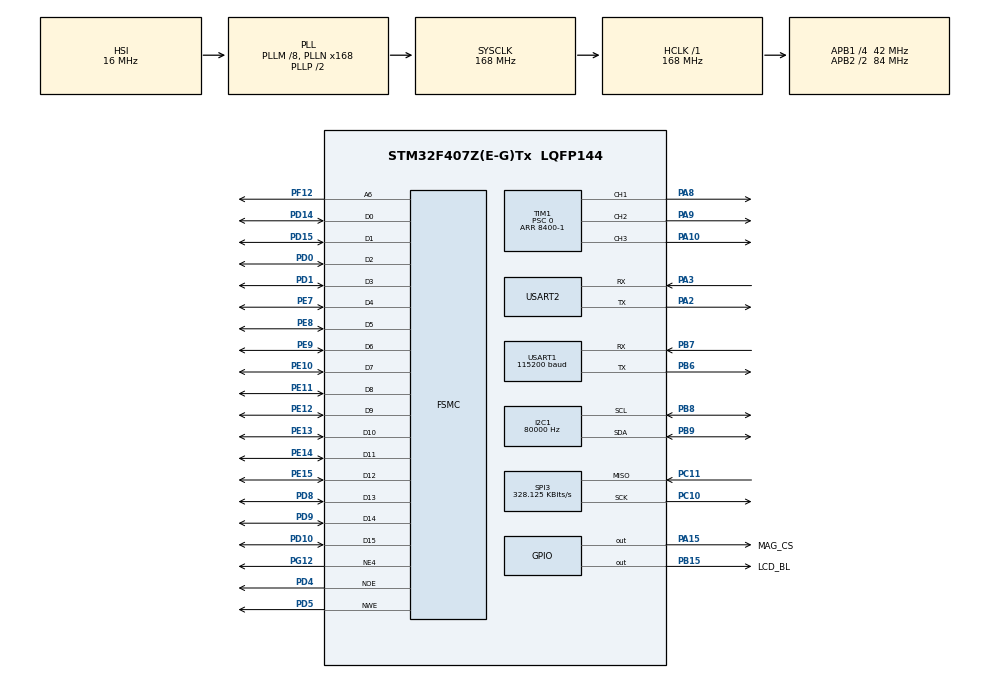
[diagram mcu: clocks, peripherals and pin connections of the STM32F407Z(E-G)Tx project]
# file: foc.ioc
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Dma.Request0=USART1_TX
Dma.Request1=USART2_RX
Dma.Request2=USART2_TX
Dma.USART1_TX.0.Direction=DMA_MEMORY_TO_PERIPH
Dma.USART1_TX.0.FIFOMode=DMA_FIFOMODE_DISABLE
Dma.USART1_TX.0.Instance=DMA2_Stream7
Dma.USART1_TX.0.MemDataAlignment=DMA_MDATAALIGN_BYTE
Dma.USART1_TX.0.MemInc=DMA_MINC_ENABLE
Dma.USART1_TX.0.Mode=DMA_NORMAL
Dma.USART1_TX.0.PeriphDataAlignment=DMA_PDATAALIGN_BYTE
Dma.USART1_TX.0.PeriphInc=DMA_PINC_DISABLE
Dma.USART1_TX.0.Priority=DMA_PRIORITY_LOW
Dma.USART2_RX.1.Direction=DMA_PERIPH_TO_MEMORY
Dma.USART2_RX.1.FIFOMode=DMA_FIFOMODE_DISABLE
Dma.USART2_RX.1.Instance=DMA1_Stream5
Dma.USART2_RX.1.MemDataAlignment=DMA_MDATAALIGN_BYTE
Dma.USART2_RX.1.MemInc=DMA_MINC_ENABLE
Dma.USART2_RX.1.Mode=DMA_NORMAL
Dma.USART2_RX.1.PeriphDataAlignment=DMA_PDATAALIGN_BYTE
Dma.USART2_RX.1.PeriphInc=DMA_PINC_DISABLE
Dma.USART2_RX.1.Priority=DMA_PRIORITY_LOW
Dma.USART2_TX.2.Direction=DMA_MEMORY_TO_PERIPH
Dma.USART2_TX.2.FIFOMode=DMA_FIFOMODE_DISABLE
Dma.USART2_TX.2.Instance=DMA1_Stream6
Dma.USART2_TX.2.MemDataAlignment=DMA_MDATAALIGN_BYTE
Dma.USART2_TX.2.MemInc=DMA_MINC_ENABLE
Dma.USART2_TX.2.Mode=DMA_NORMAL
Dma.USART2_TX.2.PeriphDataAlignment=DMA_PDATAALIGN_BYTE
Dma.USART2_TX.2.PeriphInc=DMA_PINC_DISABLE
Dma.USART2_TX.2.Priority=DMA_PRIORITY_LOW
FREERTOS.Tasks01=dbug_info,0,1000,dbug_info_fun,As weak,NULL,Dynamic,NULL,NULL;entey_task,3,512,entey_task_fun,As weak,NULL,Dynamic,NULL,NULL
FREERTOS.configENABLE_FPU=1
FREERTOS.configGENERATE_RUN_TIME_STATS=1
FREERTOS.configTOTAL_HEAP_SIZE=30000
FREERTOS.configUSE_RECURSIVE_MUTEXES=1
FREERTOS.configUSE_STATS_FORMATTING_FUNCTIONS=1
FREERTOS.configUSE_TRACE_FACILITY=1
FSMC.ExtendedMode1=FSMC_EXTENDED_MODE_ENABLE
I2C1.ClockSpeed=80000
I2C1.I2C_Mode=I2C_Standard
Mcu.Family=STM32F4
Mcu.Name=STM32F407Z(E-G)Tx
Mcu.Package=LQFP144
NVIC.DMA1_Stream5_IRQn=true\:5\:0\:false\:false\:true\:true\:false\:true\:true
NVIC.DMA1_Stream6_IRQn=true\:5\:0\:false\:false\:true\:true\:false\:true\:true
NVIC.DMA2_Stream7_IRQn=true\:5\:0\:false\:false\:true\:true\:false\:true\:true
NVIC.PriorityGroup=NVIC_PRIORITYGROUP_4
NVIC.TIM1_UP_TIM10_IRQn=true\:5\:0\:false\:false\:true\:true\:true\:true\:true
NVIC.TIM7_IRQn=true\:4\:0\:true\:false\:true\:false\:true\:true\:true
NVIC.TIM8_TRG_COM_TIM14_IRQn=true\:4\:0\:true\:false\:true\:false\:false\:true\:true
NVIC.TimeBase=TIM8_TRG_COM_TIM14_IRQn
NVIC.TimeBaseIP=TIM14
NVIC.USART1_IRQn=true\:5\:0\:false\:false\:true\:true\:true\:true\:true
NVIC.USART2_IRQn=true\:5\:0\:false\:false\:true\:true\:true\:true\:true
PA10.Signal=S_TIM1_CH3
PA13.Mode=Serial_Wire
PA13.Signal=SYS_JTMS-SWDIO
PA14.Mode=Serial_Wire
PA14.Signal=SYS_JTCK-SWCLK
PA15.GPIO_Label=MAG_CS
PA15.GPIO_PuPd=GPIO_PULLUP
PA15.GPIO_Speed=GPIO_SPEED_FREQ_VERY_HIGH
PA15.PinState=GPIO_PIN_SET
PA15.Signal=GPIO_Output
PA2.Mode=Asynchronous
PA2.Signal=USART2_TX
PA3.Mode=Asynchronous
PA3.Signal=USART2_RX
PA8.Signal=S_TIM1_CH1
PA9.Signal=S_TIM1_CH2
PB15.GPIO_Label=LCD_BL
PB15.GPIO_PuPd=GPIO_PULLUP
PB15.GPIO_Speed=GPIO_SPEED_FREQ_VERY_HIGH
PB15.PinState=GPIO_PIN_SET
PB15.Signal=GPIO_Output
PB6.Mode=Asynchronous
PB6.Signal=USART1_TX
PB7.Mode=Asynchronous
PB7.Signal=USART1_RX
PB8.GPIO_Pu=GPIO_PULLUP
PB8.Mode=I2C
PB8.Signal=I2C1_SCL
PB9.GPIO_Pu=GPIO_PULLUP
PB9.Mode=I2C
PB9.Signal=I2C1_SDA
PC10.GPIO_PuPd=GPIO_PULLUP
PC10.Mode=RX_Only_Simplex_Unidirect_Master
PC10.Signal=SPI3_SCK
PC11.GPIO_PuPd=GPIO_PULLUP
PC11.Mode=RX_Only_Simplex_Unidirect_Master
PC11.Signal=SPI3_MISO
PC14-OSC32_IN.Mode=LSE-External-Oscillator
PC14-OSC32_IN.Signal=RCC_OSC32_IN
PC15-OSC32_OUT.Mode=LSE-External-Oscillator
PC15-OSC32_OUT.Signal=RCC_OSC32_OUT
PD0.Signal=FSMC_D2_DA2
PD1.Signal=FSMC_D3_DA3
PD10.Signal=FSMC_D15_DA15
PD14.Signal=FSMC_D0_DA0
PD15.Signal=FSMC_D1_DA1
PD4.Signal=FSMC_NOE
PD5.Signal=FSMC_NWE
PD8.Signal=FSMC_D13_DA13
PD9.Signal=FSMC_D14_DA14
PE10.Signal=FSMC_D7_DA7
PE11.Signal=FSMC_D8_DA8
PE12.Signal=FSMC_D9_DA9
PE13.Signal=FSMC_D10_DA10
PE14.Signal=FSMC_D11_DA11
PE15.Signal=FSMC_D12_DA12
PE7.Signal=FSMC_D4_DA4
PE8.Signal=FSMC_D5_DA5
PE9.Signal=FSMC_D6_DA6
PF12.Signal=FSMC_A6
PG12.Mode=NorPsramChipSelect4_1
PG12.Signal=FSMC_NE4
PH0-OSC_IN.Mode=HSE-External-Oscillator
PH0-OSC_IN.Signal=RCC_OSC_IN
PH1-OSC_OUT.Mode=HSE-External-Oscillator
PH1-OSC_OUT.Signal=RCC_OSC_OUT
ProjectManager.HeapSize=0x200
ProjectManager.StackSize=0x800
ProjectManager.TargetToolchain=CMake
RCC.48MHZClocksFreq_Value=84000000
RCC.AHBFreq_Value=168000000
RCC.APB1CLKDivider=RCC_HCLK_DIV4
RCC.APB1Freq_Value=42000000
RCC.APB1TimFreq_Value=84000000
RCC.APB2CLKDivider=RCC_HCLK_DIV2
RCC.APB2Freq_Value=84000000
RCC.APB2TimFreq_Value=168000000
RCC.CortexFreq_Value=168000000
RCC.HCLKFreq_Value=168000000
RCC.HSE_VALUE=25000000
RCC.HSI_VALUE=16000000
RCC.PLLM=8
RCC.PLLN=168
RCC.SYSCLKFreq_VALUE=168000000
RCC.SYSCLKSource=RCC_SYSCLKSOURCE_PLLCLK
RCC.VCOOutputFreq_Value=336000000
SH.FSMC_A6.0=FSMC_A6,A6_1
SH.FSMC_D0_DA0.0=FSMC_D0,16b-d1
SH.FSMC_D10_DA10.0=FSMC_D10,16b-d1
SH.FSMC_D11_DA11.0=FSMC_D11,16b-d1
SH.FSMC_D12_DA12.0=FSMC_D12,16b-d1
SH.FSMC_D13_DA13.0=FSMC_D13,16b-d1
SH.FSMC_D14_DA14.0=FSMC_D14,16b-d1
SH.FSMC_D15_DA15.0=FSMC_D15,16b-d1
SH.FSMC_D1_DA1.0=FSMC_D1,16b-d1
SH.FSMC_D2_DA2.0=FSMC_D2,16b-d1
SH.FSMC_D3_DA3.0=FSMC_D3,16b-d1
SH.FSMC_D4_DA4.0=FSMC_D4,16b-d1
SH.FSMC_D5_DA5.0=FSMC_D5,16b-d1
SH.FSMC_D6_DA6.0=FSMC_D6,16b-d1
SH.FSMC_D7_DA7.0=FSMC_D7,16b-d1
SH.FSMC_D8_DA8.0=FSMC_D8,16b-d1
SH.FSMC_D9_DA9.0=FSMC_D9,16b-d1
SH.FSMC_NOE.0=FSMC_NOE,Lcd1
SH.FSMC_NWE.0=FSMC_NWE,Lcd1
SH.S_TIM1_CH1.0=TIM1_CH1,PWM Generation1 CH1
SH.S_TIM1_CH2.0=TIM1_CH2,PWM Generation2 CH2
SH.S_TIM1_CH3.0=TIM1_CH3,PWM Generation3 CH3
SPI3.BaudRatePrescaler=SPI_BAUDRATEPRESCALER_128
SPI3.CLKPhase=SPI_PHASE_2EDGE
SPI3.CLKPolarity=SPI_POLARITY_LOW
SPI3.CalculateBaudRate=328.125 KBits/s
SPI3.Direction=SPI_DIRECTION_2LINES_RXONLY
SPI3.Mode=SPI_MODE_MASTER
SPI3.VirtualType=VM_MASTER
STMicroelectronics.X-CUBE-ALGOBUILD.1.4.0.LibraryCcDSPOoLibraryJjDSPOoLibrary=true
TIM1.Channel-PWM\ Generation1\ CH1=TIM_CHANNEL_1
TIM1.Channel-PWM\ Generation2\ CH2=TIM_CHANNEL_2
TIM1.Channel-PWM\ Generation3\ CH3=TIM_CHANNEL_3
TIM1.Period=8400-1
TIM1.Prescaler=0
TIM1.Pulse-PWM\ Generation1\ CH1=4200-1
TIM1.Pulse-PWM\ Generation2\ CH2=0
TIM1.Pulse-PWM\ Generation3\ CH3=0
TIM1.TIM_MasterOutputTrigger=TIM_TRGO_RESET
TIM7.Period=100-1
TIM7.Prescaler=168-1
USART1.BaudRate=115200
USART1.VirtualMode=VM_ASYNC
USART2.VirtualMode=VM_ASYNC
VP_FREERTOS_VS_CMSIS_V1.Mode=CMSIS_V1
VP_STMicroelectronics.X-CUBE-ALGOBUILD_VS_DSPOoLibraryJjLibrary_1.4.0_1.4.0.Mode=DSPOoLibraryJjLibrary
VP_SYS_VS_tim14.Mode=TIM14
VP_TIM1_VS_ClockSourceINT.Mode=Internal
VP_TIM7_VS_ClockSourceINT.Mode=Enable_Timer
board=custom

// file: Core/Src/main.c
/* USER CODE BEGIN Header */
/* USER CODE END Header */
#include "main.h"
#include "cmsis_os.h"
#include "dma.h"
#include "i2c.h"
#include "spi.h"
#include "tim.h"
#include "usart.h"
#include "gpio.h"
#include "fsmc.h"

/* USER CODE BEGIN Includes */
#include "uart_dbg.h"
/* USER CODE END Includes */

void SystemClock_Config(void);
void MX_FREERTOS_Init(void);

int main(void)
{

  /* MCU Configuration--------------------------------------------------------*/

  /* Reset of all peripherals, Initializes the Flash interface and the Systick. */
  HAL_Init();

  /* Configure the system clock */
  SystemClock_Config();

  /* Initialize all configured peripherals */
  MX_GPIO_Init();
  MX_DMA_Init();
  MX_TIM1_Init();
  MX_USART1_UART_Init();
  MX_I2C1_Init();
  MX_SPI3_Init();
  MX_USART2_UART_Init();
  MX_TIM7_Init();
  MX_FSMC_Init();

  /* Call init function for freertos objects (in cmsis_os2.c) */
  MX_FREERTOS_Init();

  /* Start scheduler */
  osKernelStart();

  /* We should never get here as control is now taken by the scheduler */

  /* Infinite loop */

}

void SystemClock_Config(void)
{
  RCC_OscInitTypeDef RCC_OscInitStruct = {0};
  RCC_ClkInitTypeDef RCC_ClkInitStruct = {0};

  /** Configure the main internal regulator output voltage
  */
  __HAL_RCC_PWR_CLK_ENABLE();
  __HAL_PWR_VOLTAGESCALING_CONFIG(PWR_REGULATOR_VOLTAGE_SCALE1);

  /** Initializes the RCC Oscillators according to the specified parameters
  * in the RCC_OscInitTypeDef structure.
  */
  RCC_OscInitStruct.OscillatorType = RCC_OSCILLATORTYPE_HSI;
  RCC_OscInitStruct.HSIState = RCC_HSI_ON;
  RCC_OscInitStruct.HSICalibrationValue = RCC_HSICALIBRATION_DEFAULT;
  RCC_OscInitStruct.PLL.PLLState = RCC_PLL_ON;
  RCC_OscInitStruct.PLL.PLLSource = RCC_PLLSOURCE_HSI;
  RCC_OscInitStruct.PLL.PLLM = 8;
  RCC_OscInitStruct.PLL.PLLN = 168;
  RCC_OscInitStruct.PLL.PLLP = RCC_PLLP_DIV2;
  RCC_OscInitStruct.PLL.PLLQ = 4;
  if (HAL_RCC_OscConfig(&RCC_OscInitStruct) != HAL_OK)
  {
    Error_Handler();
  }

  /** Initializes the CPU, AHB and APB buses clocks
  */
  RCC_ClkInitStruct.ClockType = RCC_CLOCKTYPE_HCLK|RCC_CLOCKTYPE_SYSCLK
                              |RCC_CLOCKTYPE_PCLK1|RCC_CLOCKTYPE_PCLK2;
  RCC_ClkInitStruct.SYSCLKSource = RCC_SYSCLKSOURCE_PLLCLK;
  RCC_ClkInitStruct.AHBCLKDivider = RCC_SYSCLK_DIV1;
  RCC_ClkInitStruct.APB1CLKDivider = RCC_HCLK_DIV4;
  RCC_ClkInitStruct.APB2CLKDivider = RCC_HCLK_DIV2;

  if (HAL_RCC_ClockConfig(&RCC_ClkInitStruct, FLASH_LATENCY_5) != HAL_OK)
  {
    Error_Handler();
  }
}

void HAL_TIM_PeriodElapsedCallback(TIM_HandleTypeDef *htim)
{
  if (htim->Instance == TIM14)
  {
    HAL_IncTick();
  }
  /* USER CODE BEGIN Callback 1 */
  else {
    void TIM_PeriodElapsedCallback(TIM_HandleTypeDef *htim);
    TIM_PeriodElapsedCallback(htim);
  }
  /* USER CODE END Callback 1 */
}

void Error_Handler(void)
{
}

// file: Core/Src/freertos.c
/* USER CODE BEGIN Header */
/**
  ******************************************************************************
  * File Name          : freertos.c
  * Description        : Code for freertos applications
  ******************************************************************************
  * @attention
  *
  * Copyright (c) 2025 STMicroelectronics.
  * All rights reserved.
  *
  * This software is licensed under terms that can be found in the LICENSE file
  * in the root directory of this software component.
  * If no LICENSE file comes with this software, it is provided AS-IS.
  *
  ******************************************************************************
  */
/* USER CODE END Header */

#include "FreeRTOS.h"
#include "task.h"
#include "main.h"
#include "cmsis_os.h"

osThreadId dbug_infoHandle;
osThreadId entey_taskHandle;

void dbug_info_fun(void const * argument);
void entey_task_fun(void const * argument);

void MX_FREERTOS_Init(void); /* (MISRA C 2004 rule 8.1) */

/* GetIdleTaskMemory prototype (linked to static allocation support) */
void vApplicationGetIdleTaskMemory( StaticTask_t **ppxIdleTaskTCBBuffer, StackType_t **ppxIdleTaskStackBuffer, uint32_t *pulIdleTaskStackSize );

/* Hook prototypes */
void configureTimerForRunTimeStats(void);
unsigned long getRunTimeCounterValue(void);

/* USER CODE BEGIN 1 */
/* Functions needed when configGENERATE_RUN_TIME_STATS is on */
__weak void configureTimerForRunTimeStats(void)
{

}

__weak unsigned long getRunTimeCounterValue(void)
{
return 0;
}
/* USER CODE END 1 */

/* USER CODE BEGIN GET_IDLE_TASK_MEMORY */
static StaticTask_t xIdleTaskTCBBuffer;
static StackType_t xIdleStack[configMINIMAL_STACK_SIZE];

void vApplicationGetIdleTaskMemory( StaticTask_t **ppxIdleTaskTCBBuffer, StackType_t **ppxIdleTaskStackBuffer, uint32_t *pulIdleTaskStackSize )
{
  *ppxIdleTaskTCBBuffer = &xIdleTaskTCBBuffer;
  *ppxIdleTaskStackBuffer = &xIdleStack[0];
  *pulIdleTaskStackSize = configMINIMAL_STACK_SIZE;
  /* place for user code */
}
/* USER CODE END GET_IDLE_TASK_MEMORY */

void MX_FREERTOS_Init(void) {
  /* USER CODE BEGIN Init */
  extern void setup(void);
  setup();
  /* USER CODE END Init */

  /* Create the thread(s) */
  /* definition and creation of dbug_info */
  osThreadDef(dbug_info, dbug_info_fun, osPriorityNormal, 0, 1000);
  dbug_infoHandle = osThreadCreate(osThread(dbug_info), NULL);

  /* definition and creation of entey_task */
  osThreadDef(entey_task, entey_task_fun, osPriorityRealtime, 0, 512);
  entey_taskHandle = osThreadCreate(osThread(entey_task), NULL);

}

__weak void dbug_info_fun(void const * argument)
{
  for(;;)
  {
    osDelay(1);
  }
}

__weak void entey_task_fun(void const * argument)
{
  for(;;)
  {
    osDelay(1);
  }
}
